# MCU_CTRL_MMR0_MCU_CTRL_MMR_CFG0_04500000h register map
Vendor: Texas Instruments
Registers are 32-bit, read-write, reset 0x0 unless marked. A register's access mark holds for its fields unless they carry their own. Offsets are as the file gives them; [hi:lo] are bit positions; {n}, {i} and the like mark numbered series.

## mcu_ctrl_mmr_CFG0 (part 2 of 2)
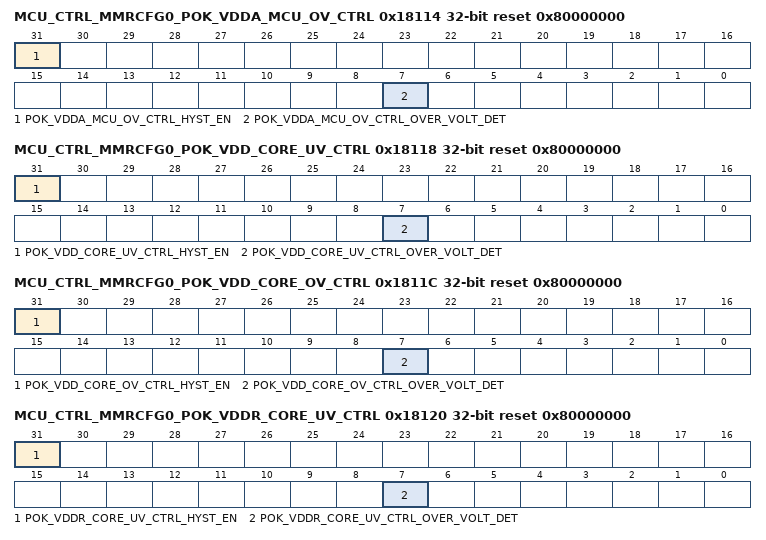
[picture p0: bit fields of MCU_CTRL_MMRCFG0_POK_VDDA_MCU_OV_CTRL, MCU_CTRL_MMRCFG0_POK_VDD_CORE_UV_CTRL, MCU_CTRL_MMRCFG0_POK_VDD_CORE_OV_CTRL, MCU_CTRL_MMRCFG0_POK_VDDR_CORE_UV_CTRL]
0x18114 MCU_CTRL_MMRCFG0_POK_VDDA_MCU_OV_CTRL reset 0x80000000 — Hysterisis, Threshold, and Control of VDDA_MCU 1P8 Under/Over Voltage Monitors in POR (POKHV, POKLVA)
  [31] POK_VDDA_MCU_OV_CTRL_HYST_EN — Enable POK hysteresisField values (others are reserved):1'b0 - DISABLE1'b1 - ENABLE Reset Source: mod_por_rst_n
  [7] POK_VDDA_MCU_OV_CTRL_OVER_VOLT_DET — Over / under voltage detection modeField values (others are reserved):1'b0 - UNDERVOLTAGE_MODE1'b1 - OVERVOLTAGE_MODE Reset Source: mod_por_rst_n
0x18118 MCU_CTRL_MMRCFG0_POK_VDD_CORE_UV_CTRL reset 0x80000000 — Hysterisis, Threshold, and Control of VDD_CORE Under/Over Voltage Monitors in POR (POKLVB) and POK_VDD_CORE_UV
  [31] POK_VDD_CORE_UV_CTRL_HYST_EN — Enable POK hysteresisField values (others are reserved):1'b0 - DISABLE1'b1 - ENABLE Reset Source: mod_por_rst_n
  [7] POK_VDD_CORE_UV_CTRL_OVER_VOLT_DET — Over / under voltage detection modeField values (others are reserved):1'b0 - UNDERVOLTAGE_MODE1'b1 - OVERVOLTAGE_MODE Reset Source: mod_por_rst_n
0x1811C MCU_CTRL_MMRCFG0_POK_VDD_CORE_OV_CTRL reset 0x80000000 — Hysterisis, Threshold, and Control of VDD_CORE Under/Over Voltage Monitors in POR (POKLVB) and POK_VDD_CORE_UV
  [31] POK_VDD_CORE_OV_CTRL_HYST_EN — Enable POK hysteresisField values (others are reserved):1'b0 - DISABLE1'b1 - ENABLE Reset Source: mod_por_rst_n
  [7] POK_VDD_CORE_OV_CTRL_OVER_VOLT_DET — Over / under voltage detection modeField values (others are reserved):1'b0 - UNDERVOLTAGE_MODE1'b1 - OVERVOLTAGE_MODE Reset Source: mod_por_rst_n
0x18120 MCU_CTRL_MMRCFG0_POK_VDDR_CORE_UV_CTRL reset 0x80000000 — Hysterisis, Threshold, and Control of VDDR_CORE Under/Over Voltage Monitor
  [31] POK_VDDR_CORE_UV_CTRL_HYST_EN — Enable POK hysteresisField values (others are reserved):1'b0 - DISABLE1'b1 - ENABLE Reset Source: mod_por_rst_n
  [7] POK_VDDR_CORE_UV_CTRL_OVER_VOLT_DET — Over / under voltage detection modeField values (others are reserved):1'b0 - UNDERVOLTAGE_MODE1'b1 - OVERVOLTAGE_MODE Reset Source: mod_por_rst_n
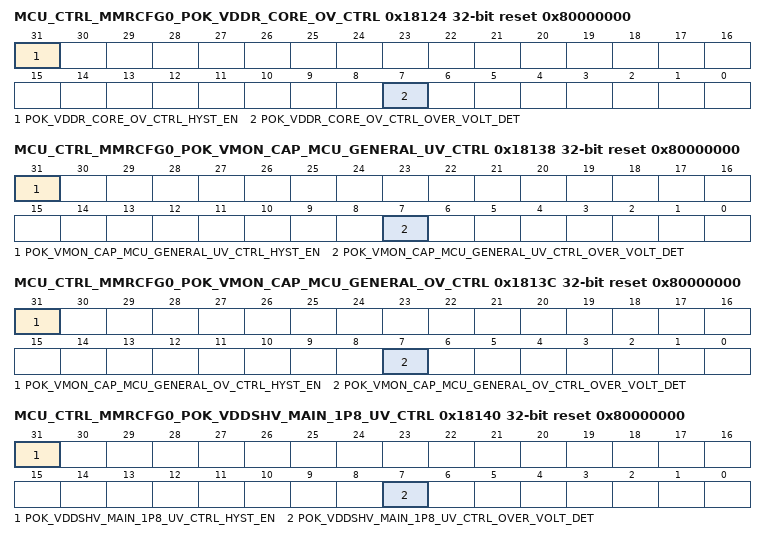
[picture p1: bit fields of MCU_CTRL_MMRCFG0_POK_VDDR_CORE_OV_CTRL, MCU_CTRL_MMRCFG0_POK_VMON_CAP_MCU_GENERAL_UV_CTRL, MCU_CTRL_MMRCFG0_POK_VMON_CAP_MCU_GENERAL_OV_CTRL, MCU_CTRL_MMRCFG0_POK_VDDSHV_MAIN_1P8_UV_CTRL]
0x18124 MCU_CTRL_MMRCFG0_POK_VDDR_CORE_OV_CTRL reset 0x80000000 — Hysterisis, Threshold, and Control of VDDR_CORE Under/Over Voltage Monitor
  [31] POK_VDDR_CORE_OV_CTRL_HYST_EN — Enable POK hysteresisField values (others are reserved):1'b0 - DISABLE1'b1 - ENABLE Reset Source: mod_por_rst_n
  [7] POK_VDDR_CORE_OV_CTRL_OVER_VOLT_DET — Over / under voltage detection modeField values (others are reserved):1'b0 - UNDERVOLTAGE_MODE1'b1 - OVERVOLTAGE_MODE Reset Source: mod_por_rst_n
0x18138 MCU_CTRL_MMRCFG0_POK_VMON_CAP_MCU_GENERAL_UV_CTRL reset 0x80000000 — Hysterisis, Threshold, and Control of VMON_CAP_MCU_GENERAL Under/Over Voltage Monitor
  [31] POK_VMON_CAP_MCU_GENERAL_UV_CTRL_HYST_EN — Enable POK hysteresisField values (others are reserved):1'b0 - DISABLE1'b1 - ENABLE Reset Source: mod_por_rst_n
  [7] POK_VMON_CAP_MCU_GENERAL_UV_CTRL_OVER_VOLT_DET — Over / under voltage detection modeField values (others are reserved):1'b0 - UNDERVOLTAGE_MODE1'b1 - OVERVOLTAGE_MODE Reset Source: mod_por_rst_n
0x1813C MCU_CTRL_MMRCFG0_POK_VMON_CAP_MCU_GENERAL_OV_CTRL reset 0x80000000 — Hysterisis, Threshold, and Control of VMON_CAP_MCU_GENERAL Under/Over Voltage Monitor
  [31] POK_VMON_CAP_MCU_GENERAL_OV_CTRL_HYST_EN — Enable POK hysteresisField values (others are reserved):1'b0 - DISABLE1'b1 - ENABLE Reset Source: mod_por_rst_n
  [7] POK_VMON_CAP_MCU_GENERAL_OV_CTRL_OVER_VOLT_DET — Over / under voltage detection modeField values (others are reserved):1'b0 - UNDERVOLTAGE_MODE1'b1 - OVERVOLTAGE_MODE Reset Source: mod_por_rst_n
0x18140 MCU_CTRL_MMRCFG0_POK_VDDSHV_MAIN_1P8_UV_CTRL reset 0x80000000 — Hysterisis, Threshold, and Control of VDDSHV_MAIN_1P8 Under/Over Voltage Monitor
  [31] POK_VDDSHV_MAIN_1P8_UV_CTRL_HYST_EN — Enable POK hysteresisField values (others are reserved):1'b0 - DISABLE1'b1 - ENABLE Reset Source: mod_por_rst_n
  [7] POK_VDDSHV_MAIN_1P8_UV_CTRL_OVER_VOLT_DET — Over / under voltage detection modeField values (others are reserved):1'b0 - UNDERVOLTAGE_MODE1'b1 - OVERVOLTAGE_MODE Reset Source: mod_por_rst_n
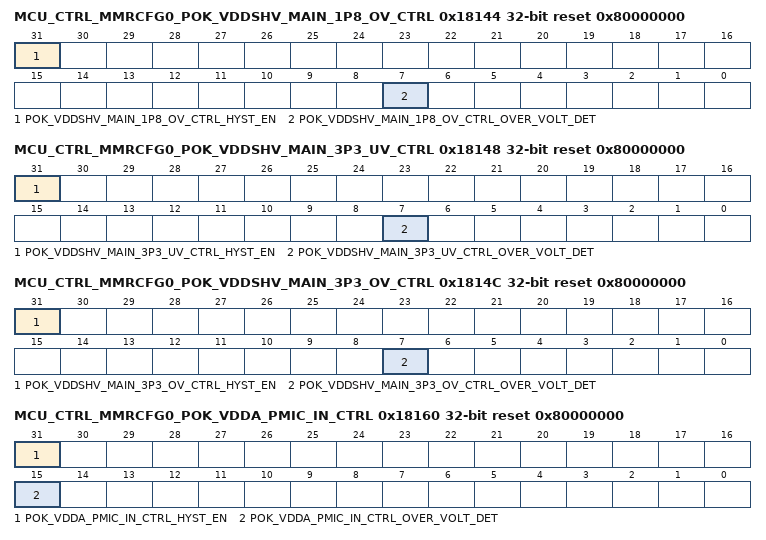
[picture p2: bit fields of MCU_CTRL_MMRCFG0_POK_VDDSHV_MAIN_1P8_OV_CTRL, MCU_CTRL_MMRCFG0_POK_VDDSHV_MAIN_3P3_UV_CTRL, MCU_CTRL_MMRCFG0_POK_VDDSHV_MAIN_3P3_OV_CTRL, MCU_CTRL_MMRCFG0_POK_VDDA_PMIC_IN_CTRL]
0x18144 MCU_CTRL_MMRCFG0_POK_VDDSHV_MAIN_1P8_OV_CTRL reset 0x80000000 — Hysterisis, Threshold, and Control of VDDSHV_MAIN_1P8 Under/Over Voltage Monitor
  [31] POK_VDDSHV_MAIN_1P8_OV_CTRL_HYST_EN — Enable POK hysteresisField values (others are reserved):1'b0 - DISABLE1'b1 - ENABLE Reset Source: mod_por_rst_n
  [7] POK_VDDSHV_MAIN_1P8_OV_CTRL_OVER_VOLT_DET — Over / under voltage detection modeField values (others are reserved):1'b0 - UNDERVOLTAGE_MODE1'b1 - OVERVOLTAGE_MODE Reset Source: mod_por_rst_n
0x18148 MCU_CTRL_MMRCFG0_POK_VDDSHV_MAIN_3P3_UV_CTRL reset 0x80000000 — Hysterisis, Threshold, and Control of VDDSHV_MAIN_3P3 Under/Over Voltage Monitor
  [31] POK_VDDSHV_MAIN_3P3_UV_CTRL_HYST_EN — Enable POK hysteresisField values (others are reserved):1'b0 - DISABLE1'b1 - ENABLE Reset Source: mod_por_rst_n
  [7] POK_VDDSHV_MAIN_3P3_UV_CTRL_OVER_VOLT_DET — Over / under voltage detection modeField values (others are reserved):1'b0 - UNDERVOLTAGE_MODE1'b1 - OVERVOLTAGE_MODE Reset Source: mod_por_rst_n
0x1814C MCU_CTRL_MMRCFG0_POK_VDDSHV_MAIN_3P3_OV_CTRL reset 0x80000000 — Hysterisis, Threshold, and Control of VDDSHV_MAIN_3P3 Under/Over Voltage Monitor
  [31] POK_VDDSHV_MAIN_3P3_OV_CTRL_HYST_EN — Enable POK hysteresisField values (others are reserved):1'b0 - DISABLE1'b1 - ENABLE Reset Source: mod_por_rst_n
  [7] POK_VDDSHV_MAIN_3P3_OV_CTRL_OVER_VOLT_DET — Over / under voltage detection modeField values (others are reserved):1'b0 - UNDERVOLTAGE_MODE1'b1 - OVERVOLTAGE_MODE Reset Source: mod_por_rst_n
0x18160 MCU_CTRL_MMRCFG0_POK_VDDA_PMIC_IN_CTRL reset 0x80000000 — Hysterisis and Control of VDDA_PMIC_IN Under/Over Voltage Monitor
  [31] POK_VDDA_PMIC_IN_CTRL_HYST_EN — Enable POK hysteresisField values (others are reserved):1'b0 - DISABLE1'b1 - ENABLE Reset Source: mod_por_rst_n
  [15] POK_VDDA_PMIC_IN_CTRL_OVER_VOLT_DET — Over / under voltage detection modeField values (others are reserved):1'b0 - UNDERVOLTAGE_MODE1'b1 - OVERVOLTAGE_MODE Reset Source: mod_por_rst_n
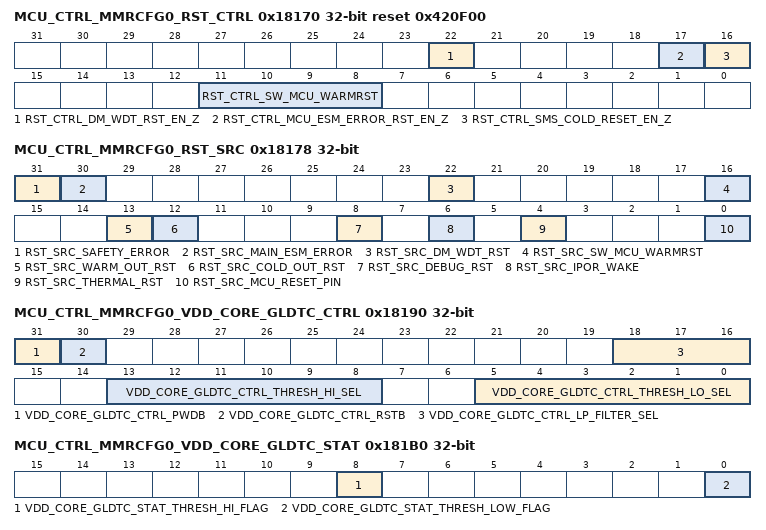
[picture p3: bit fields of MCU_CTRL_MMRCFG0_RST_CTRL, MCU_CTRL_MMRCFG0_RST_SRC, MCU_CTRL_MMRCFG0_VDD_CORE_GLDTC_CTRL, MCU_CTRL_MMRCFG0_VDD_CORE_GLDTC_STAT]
0x18170 MCU_CTRL_MMRCFG0_RST_CTRL reset 0x420F00 — Controls Reset Assertion and Propogation
  [22] RST_CTRL_DM_WDT_RST_EN_Z — Block Reset from DM WDT propogating to MCU domainField values (others are reserved):1'b0 - PROPOGATE1'b1 - BLOCK Reset Source: mcu_chip1_rst_n
  [17] RST_CTRL_MCU_ESM_ERROR_RST_EN_Z — Block Reset of MCU by ESMField values (others are reserved):1'b0 - PROPOGATE1'b1 - BLOCK Reset Source: mcu_chip1_rst_n
  [16] RST_CTRL_SMS_COLD_RESET_EN_Z — Block Reset of MCU by SMSField values (others are reserved):1'b0 - PROPOGATE1'b1 - BLOCK Reset Source: mcu_chip1_rst_n
  [11:8] RST_CTRL_SW_MCU_WARMRST — Causes full device Warm Reset. This is a fault tolerant bitfield. Automatically resets to 4'b1111 after write.Field values (others are reserved):4'b0110 - FORCE_RESET4'b1111 - INACTIVE Reset Source: mcu_chip1_rst_n
0x18174 MCU_CTRL_MMRCFG0_RST_STAT ro — Reset Status
  [0] RST_STAT_MAIN_RESETSTATZ — Status of Main Domain Reset:Field values (others are reserved):1'b0 - BLOCKED1'b1 - PROPOGATE Reset Source: mcu_chip1_rst_n
0x18178 MCU_CTRL_MMRCFG0_RST_SRC access not given — Captures Reason for Warm and Main Domain Power On Resets
  [31] RST_SRC_SAFETY_ERROR — Reset Caused by MCU ESM Error. Write 1 to Clear.Field values (others are reserved):1'b0 - UNKNOWN1'b1 - DETECTED Reset Source: mod_por_rst_n (access R/W1TC)
  [30] RST_SRC_MAIN_ESM_ERROR — Reset Caused by Main ESM Error. Write 1 to Clear.Field values (others are reserved):1'b0 - UNKNOWN1'b1 - DETECTED Reset Source: mod_por_rst_n (access R/W1TC)
  [22] RST_SRC_DM_WDT_RST — Watchdog Initiated Reset. Write 1 to Clear.Field values (others are reserved):1'b0 - UNKNOWN1'b1 - DETECTED Reset Source: mod_por_rst_n (access R/W1TC)
  [16] RST_SRC_SW_MCU_WARMRST — Software Warm Reset. Write 1 to Clear.Field values (others are reserved):1'b0 - UNKNOWN1'b1 - DETECTED Reset Source: mod_por_rst_n (access R/W1TC)
  [13] RST_SRC_WARM_OUT_RST — SMS Warm Reset. Write 1 to Clear.Field values (others are reserved):1'b0 - UNKNOWN1'b1 - DETECTED Reset Source: mod_por_rst_n (access R/W1TC)
  [12] RST_SRC_COLD_OUT_RST — When set, indicates that a DMSC Cold reset occurred and reset either main or mcu domains (or both).Write 1 to clear this bit.Field values (others are reserved):1'b0 - UNKNOWN1'b1 - DETECTED Reset Source: mod_por_rst_n (access R/W1TC)
  [8] RST_SRC_DEBUG_RST — Debug Subsystem Initiated Reset. Write 1 to Clear.Field values (others are reserved):1'b0 - UNKNOWN1'b1 - DETECTED Reset Source: mod_por_rst_n (access R/W1TC)
  [6] RST_SRC_IPOR_WAKE — Wake Event Monitor Internal Power On Reset. Write 1 to ClearField values (others are reserved):1'b0 - UNKNOWN1'b1 - DETECTED Reset Source: por_boot_cfg_rst_n (access R/W1TC)
  [4] RST_SRC_THERMAL_RST — Thermal Reset. Write 1 to Clear.Field values (others are reserved):1'b0 - UNKNOWN1'b1 - DETECTED Reset Source: mod_por_rst_n (access R/W1TC)
  [0] RST_SRC_MCU_RESET_PIN — Reset Caused by MCU Reset Pin. Write 1 to Clear.Field values (others are reserved):1'b0 - UNKNOWN1'b1 - DETECTED Reset Source: mod_por_rst_n (access R/W1TC)
0x18190 MCU_CTRL_MMRCFG0_VDD_CORE_GLDTC_CTRL — Controls the voltage glitch detector circuit monitoring the VDD_CORE voltage domain
  [31] VDD_CORE_GLDTC_CTRL_PWDB — Power down - active low. Field values (others are reserved):1'b0 - PWRDN1'b1 - PWRUP Reset Source: mcu_chip1_rst_n
  [30] VDD_CORE_GLDTC_CTRL_RSTB — Reset - active low. To ensure proper operation, rstb must be not be de-asserted for at least 100 ns after power-up (pwdb de-asserted). Additionally, rstb must be toggled low at least 200 ns after any change in threshold or low-pass filter settings to prevent abnormal trigger events.Field values (others are reserved):1'b0 - RESET1'b1 - ACTIVE Reset Source: mcu_chip1_rst_n
  [18:16] VDD_CORE_GLDTC_CTRL_LP_FILTER_SEL — Selects the glitch detect low-pass filter bandwidthField values (others are reserved):3'b000 - BW_150KHz3'b001 - BW_125KHz3'b010 - BW_100KHz3'b011 - BW_80KHz3'b100 - BW_60KHz3'b101 - BW_45KHz3'b110 - BW_30KHz3'b111 - BW_15KHz Reset Source: mcu_chip1_rst_n
  [13:8] VDD_CORE_GLDTC_CTRL_THRESH_HI_SEL — Selects the high voltage glitch threshold as a percentage of the monitored voltageField values (others are reserved):6'b000000 - PCT_VDD_93P56'b000001 - PCT_VDD_946'b000010 - PCT_VDD_94P56'b000011 - PCT_VDD_956'b000100 - PCT_VDD_95P56'b000101 - PCT_VDD_966'b000110 - PCT_VDD_96P56'b000111 - PCT_VDD_976'b001000 - PCT_VDD_97P56'b001001 - PCT_VDD_986'b001010 - PCT_VDD_98P56'b001011 - PCT_VDD_996'b001100 - PCT_VDD_99P56'b001101 - PCT_VDD_1006'b001110 - PCT_VDD_100P56'b001111 - PCT_VDD_1016'b010000 - PCT_VDD_101P56'b010001 - PCT_VDD_1026'b010010 - PCT_VDD_102P56'b010011 - PCT_VDD_1036'b010100 - PCT_VDD_103P56'b010101 - PCT_VDD_1046'b010110 - PCT_VDD_104P56'b010111 - PCT_VDD_1056'b011000 - PCT_VDD_105P56'b011001 - PCT_VDD_1066'b011010 - PCT_VDD_106P56'b011011 - PCT_VDD_1076'b011100 - PCT_VDD_107P56'b011101 - PCT_VDD_1086'b011110 - PCT_VDD_108P56'b011111 - PCT_VDD_1096'b100000 - PCT_VDD_109P56'b100001 - PCT_VDD_1106'b100010 - PCT_VDD_1116'b100011 - PCT_VDD_1126'b100100 - PCT_VDD_1136'b100101 - PCT_VDD_1146'b100110 - PCT_VDD_1156'b100111 - PCT_VDD_1166'b101000 - PCT_VDD_1176'b101001 - PCT_VDD_1186'b101010 - PCT_VDD_1196'b101011 - PCT_VDD_1206'b101100 - PCT_VDD_1216'b101101 - PCT_VDD_1226'b101110 - PCT_VDD_1236'b101111 - PCT_VDD_1246'b110000 - PCT_VDD_1256'b110001 - PCT_VDD_1266'b110010 - PCT_VDD_1276'b110011 - PCT_VDD_1286'b110100 - PCT_VDD_1296'b110101 - PCT_VDD_1306'b110110 - PCT_VDD_1316'b110111 - PCT_VDD_1326'b111000 - PCT_VDD_1336'b111001 - PCT_VDD_1346'b111010 - PCT_VDD_1356'b111011 - PCT_VDD_1366'b111100 - PCT_VDD_1376'b111101 - PCT_VDD_1386'b111110 - PCT_VDD_1396'b111111 - PCT_VDD_140 Reset Source: mcu_chip1_rst_n
  [5:0] VDD_CORE_GLDTC_CTRL_THRESH_LO_SEL — Selects the low voltage glitch threshold as a percentage of the monitored voltageField values (others are reserved):6'b000000 - PCT_VDD_106P56'b000001 - PCT_VDD_1066'b000010 - PCT_VDD_105P56'b000011 - PCT_VDD_1056'b000100 - PCT_VDD_104P56'b000101 - PCT_VDD_1046'b000110 - PCT_VDD_103P56'b000111 - PCT_VDD_1036'b001000 - PCT_VDD_102P56'b001001 - PCT_VDD_1026'b001010 - PCT_VDD_101P56'b001011 - PCT_VDD_1016'b001100 - PCT_VDD_100P56'b001101 - PCT_VDD_1006'b001110 - PCT_VDD_99P56'b001111 - PCT_VDD_996'b010000 - PCT_VDD_98P56'b010001 - PCT_VDD_986'b010010 - PCT_VDD_97P56'b010011 - PCT_VDD_976'b010100 - PCT_VDD_96P56'b010101 - PCT_VDD_966'b010110 - PCT_VDD_95P56'b010111 - PCT_VDD_956'b011000 - PCT_VDD_94P56'b011001 - PCT_VDD_946'b011010 - PCT_VDD_93P56'b011011 - PCT_VDD_936'b011100 - PCT_VDD_92P56'b011101 - PCT_VDD_926'b011110 - PCT_VDD_91P56'b011111 - PCT_VDD_916'b100000 - PCT_VDD_90P56'b100001 - PCT_VDD_906'b100010 - PCT_VDD_896'b100011 - PCT_VDD_886'b100100 - PCT_VDD_876'b100101 - PCT_VDD_866'b100110 - PCT_VDD_856'b100111 - PCT_VDD_846'b101000 - PCT_VDD_836'b101001 - PCT_VDD_826'b101010 - PCT_VDD_816'b101011 - PCT_VDD_806'b101100 - PCT_VDD_796'b101101 - PCT_VDD_786'b101110 - PCT_VDD_776'b101111 - PCT_VDD_766'b110000 - PCT_VDD_756'b110001 - PCT_VDD_746'b110010 - PCT_VDD_736'b110011 - PCT_VDD_726'b110100 - PCT_VDD_716'b110101 - PCT_VDD_706'b110110 - PCT_VDD_696'b110111 - PCT_VDD_686'b111000 - PCT_VDD_676'b111001 - PCT_VDD_666'b111010 - PCT_VDD_656'b111011 - PCT_VDD_646'b111100 - PCT_VDD_636'b111101 - PCT_VDD_626'b111110 - PCT_VDD_616'b111111 - PCT_VDD_60 Reset Source: mcu_chip1_rst_n
0x181B0 MCU_CTRL_MMRCFG0_VDD_CORE_GLDTC_STAT ro — Shows the status of the voltage glitch detector circuit monitoring the VDD_CORE voltage domain
  [8] VDD_CORE_GLDTC_STAT_THRESH_HI_FLAG — High voltage flag. This flag is cleared by clearing the VDD_CORE_GLDTC_CTRL_rstb bit.Field values (others are reserved):1'b0 - HV_UNKNOWN (not detected)1'b1 - HV_DETECTED Reset Source: mcu_chip1_rst_n
  [0] VDD_CORE_GLDTC_STAT_THRESH_LOW_FLAG — Low voltage flag. This flag is cleared by clearing the VDD_CORE_GLDTC_CTRL_rstb bit.Field values (others are reserved):1'b0 - LV_UNKNOWN (not detected)1'b1 - LV_DETECTED Reset Source: mcu_chip1_rst_n
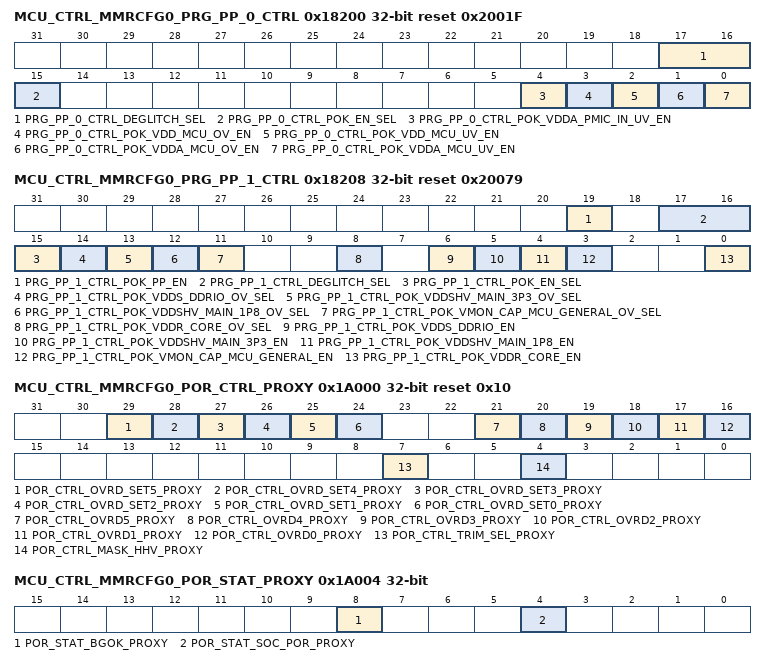
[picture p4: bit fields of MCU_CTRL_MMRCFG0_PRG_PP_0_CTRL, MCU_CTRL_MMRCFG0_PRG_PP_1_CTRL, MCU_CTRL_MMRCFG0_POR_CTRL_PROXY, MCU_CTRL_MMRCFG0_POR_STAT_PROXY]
0x18200 MCU_CTRL_MMRCFG0_PRG_PP_0_CTRL reset 0x2001F — Configures PRG_PP_0 - Fixed POKs (In POR, POKSA, and POK_VDD_CORE_OV)
  [17:16] PRG_PP_0_CTRL_DEGLITCH_SEL — Deglitch period for PRG_PP1 POKs (microseconds)Field values (others are reserved):2'b00 - DG_5_US2'b01 - DG_10_US2'b10 - DG_15_US2'b11 - DG_20_US Reset Source: mod_por_rst_n
  [15] PRG_PP_0_CTRL_POK_EN_SEL — Selects source of POK controlsField values (others are reserved):1'b0 - TIEOFFS1'b1 - PRG_PP0_CTRL_REG Reset Source: mod_por_rst_n
  [4] PRG_PP_0_CTRL_POK_VDDA_PMIC_IN_UV_EN — Enable VDDA_PMIC_IN undervoltage POK detectionField values (others are reserved):1'b0 - Disabled1'b1 - Enabled Reset Source: mod_por_rst_n
  [3] PRG_PP_0_CTRL_POK_VDD_MCU_OV_EN — Enable VDD_MCU overvoltage POK detectionField values (others are reserved):1'b0 - Disabled1'b1 - Enabled Reset Source: mod_por_rst_n
  [2] PRG_PP_0_CTRL_POK_VDD_MCU_UV_EN — Enable VDD_MCU undervoltage POK detectionField values (others are reserved):1'b0 - Disabled1'b1 - Enabled Reset Source: mod_por_rst_n
  [1] PRG_PP_0_CTRL_POK_VDDA_MCU_OV_EN — Enable 1.8V VDDA_MCU overvoltage POK detectionField values (others are reserved):1'b0 - Disabled1'b1 - Enabled Reset Source: mod_por_rst_n
  [0] PRG_PP_0_CTRL_POK_VDDA_MCU_UV_EN — Enable 1.8V VDDA_MCU undervoltage POK detectionField values (others are reserved):1'b0 - Disabled1'b1 - Enabled Reset Source: mod_por_rst_n
0x18208 MCU_CTRL_MMRCFG0_PRG_PP_1_CTRL reset 0x20079 — Configures PRG_PP_1 - Ping-Pong Capable POKs
  [19] PRG_PP_1_CTRL_POK_PP_EN — POK ping-pong enable. When set, POKs with their ov_sel option set to UV_OR_PINGPONG are automatically cycled between UV and OV detection (ping-pong). POKs with ov_sel selecting OV are unaffected by this bit.Field values (others are reserved):1'b0 - UV_FIXED1'b1 - UV_PINGPONG_OV Reset Source: mod_por_rst_n
  [17:16] PRG_PP_1_CTRL_DEGLITCH_SEL — Deglitch period for PRG_PP1 POKs (microseconds)Field values (others are reserved):2'b00 - DG_5_US2'b01 - DG_10_US2'b10 - DG_15_US2'b11 - DG_20_US Reset Source: mod_por_rst_n
  [15] PRG_PP_1_CTRL_POK_EN_SEL — Selects source of POK controlsField values (others are reserved):1'b0 - TIEOFFS1'b1 - PRG_PP0_CTRL_REG Reset Source: mod_por_rst_n
  [14] PRG_PP_1_CTRL_POK_VDDS_DDRIO_OV_SEL — POK_VDDS_DDRIO mode (undervoltage/ping-pong or over-voltage)Field values (others are reserved):1'b0 - UV_OR_PINGPONG1'b1 - OV Reset Source: mod_por_rst_n
  [13] PRG_PP_1_CTRL_POK_VDDSHV_MAIN_3P3_OV_SEL — POK_VDDSHV_MAIN_3P3 mode (undervoltage/ping-pong or over-voltage)Field values (others are reserved):1'b0 - UV_OR_PINGPONG1'b1 - OV Reset Source: mod_por_rst_n
  [12] PRG_PP_1_CTRL_POK_VDDSHV_MAIN_1P8_OV_SEL — POK_VDDSHV_MAIN_1P8 mode (undervoltage/ping-pong or over-voltage)Field values (others are reserved):1'b0 - UV_OR_PINGPONG1'b1 - OV Reset Source: mod_por_rst_n
  [11] PRG_PP_1_CTRL_POK_VMON_CAP_MCU_GENERAL_OV_SEL — POK_VMON_CAP_MCU_GENERAL mode (undervoltage/ping-pong or over-voltage)Field values (others are reserved):1'b0 - UV_OR_PINGPONG1'b1 - OV Reset Source: mod_por_rst_n
  [8] PRG_PP_1_CTRL_POK_VDDR_CORE_OV_SEL — POK_VDDR_CORE mode (undervoltage/ping-pong or over-voltage)Field values (others are reserved):1'b0 - UV_OR_PINGPONG1'b1 - OV Reset Source: mod_por_rst_n
  [6] PRG_PP_1_CTRL_POK_VDDS_DDRIO_EN — Enable POK_VDDS_DDRIO (if pok_en_sel = 1):Field values (others are reserved):1'b0 - Disabled1'b1 - Enabled Reset Source: mod_por_rst_n
  [5] PRG_PP_1_CTRL_POK_VDDSHV_MAIN_3P3_EN — Enable POK_VDDSHV_MAIN_3P3 (if pok_en_sel = 1):Field values (others are reserved):1'b0 - Disabled1'b1 - Enabled Reset Source: mod_por_rst_n
  [4] PRG_PP_1_CTRL_POK_VDDSHV_MAIN_1P8_EN — Enable POK_VDDSHV_MAIN_1P8 (if pok_en_sel = 1):Field values (others are reserved):1'b0 - Disabled1'b1 - Enabled Reset Source: mod_por_rst_n
  [3] PRG_PP_1_CTRL_POK_VMON_CAP_MCU_GENERAL_EN — Enable POK_VMON_CAP_MCU_GENERAL (if pok_en_sel = 1):Field values (others are reserved):1'b0 - Disabled1'b1 - Enabled Reset Source: mod_por_rst_n
  [0] PRG_PP_1_CTRL_POK_VDDR_CORE_EN — Enable POK_VDDR_CORE (if pok_en_sel = 1):Field values (others are reserved):1'b0 - Disabled1'b1 - Enabled Reset Source: mod_por_rst_n
0x18280 MCU_CTRL_MMRCFG0_CLKGATE_CTRL — Controls the power clock gating feature of MCU domain modules and busses
  [0] CLKGATE_CTRL_WKUP_SAFE_CBA_NOGATE — WKUP domain CBASS auto clock gate on idle disable. Field values (others are reserved):1'b0 - Auto clock gating enabled1'b1 - Auto clock gating disabled Reset Source: mod_por_rst_n
0x19008 MCU_CTRL_MMRCFG0_LOCK6_KICK0
  [31:0] LOCK6_KICK0 — - KICK0 component Reset Source: mod_g_rst_n
0x1900C MCU_CTRL_MMRCFG0_LOCK6_KICK1
  [31:0] LOCK6_KICK1 — - KICK1 component Reset Source: mod_g_rst_n
0x19100 MCU_CTRL_MMRCFG0_CLAIMREG_P6_R0_READONLY ro
  [31:0] CLAIMREG_P6_R0_READONLY — Claim bits for Partition 6 Reset Source: mod_g_rst_n
{0x19100+4i} MCU_CTRL_MMRCFG0_CLAIMREG_P6_R{i}_READONLY ro (i=2..5)
  [31:0] CLAIMREG_P6_R{i}_READONLY — Claim bits for Partition 6 Reset Source: mod_g_rst_n
0x1A000 MCU_CTRL_MMRCFG0_POR_CTRL_PROXY reset 0x10 — Configures POR module reset behavior and allows software to directly override POR comparator outputs.
  [29] POR_CTRL_OVRD_SET5_PROXY — Override value when override is active, for RESERVED output.Field values (others are reserved):1'b0 - OVERRIDE_TO_01'b1 - OVERRIDE_TO_1 Reset Source: mod_por_rst_n
  [28] POR_CTRL_OVRD_SET4_PROXY — Override value when override is active, for POKLVB output.Field values (others are reserved):1'b0 - OVERRIDE_TO_01'b1 - OVERRIDE_TO_1 Reset Source: mod_por_rst_n
  [27] POR_CTRL_OVRD_SET3_PROXY — Override value when override is active, for POKLVA output.Field values (others are reserved):1'b0 - OVERRIDE_TO_01'b1 - OVERRIDE_TO_1 Reset Source: mod_por_rst_n
  [26] POR_CTRL_OVRD_SET2_PROXY — Override value when override is active, for POKHV output.Field values (others are reserved):1'b0 - OVERRIDE_TO_01'b1 - OVERRIDE_TO_1 Reset Source: mod_por_rst_n
  [25] POR_CTRL_OVRD_SET1_PROXY — Override value when override is active, for BGOK output.Field values (others are reserved):1'b0 - OVERRIDE_TO_01'b1 - OVERRIDE_TO_1 Reset Source: mod_por_rst_n
  [24] POR_CTRL_OVRD_SET0_PROXY — Override value when override is active, for PORHV output.Field values (others are reserved):1'b0 - OVERRIDE_TO_01'b1 - OVERRIDE_TO_1 Reset Source: mod_por_rst_n
  [21] POR_CTRL_OVRD5_PROXY — Enables override of RESERVED outputField values (others are reserved):1'b0 - NORMAL_OPERATION1'b1 - OVERRIDE_OUTPUT Reset Source: mod_por_rst_n
  [20] POR_CTRL_OVRD4_PROXY — Enables override of POKLVB outputField values (others are reserved):1'b0 - NORMAL_OPERATION1'b1 - OVERRIDE_OUTPUT Reset Source: mod_por_rst_n
  [19] POR_CTRL_OVRD3_PROXY — Enables override of POKLVA outputField values (others are reserved):1'b0 - NORMAL_OPERATION1'b1 - OVERRIDE_OUTPUT Reset Source: mod_por_rst_n
  [18] POR_CTRL_OVRD2_PROXY — Enables override of POKHV outputField values (others are reserved):1'b0 - NORMAL_OPERATION1'b1 - OVERRIDE_OUTPUT Reset Source: mod_por_rst_n
  [17] POR_CTRL_OVRD1_PROXY — Enables override of BGOK outputField values (others are reserved):1'b0 - NORMAL_OPERATION1'b1 - OVERRIDE_OUTPUT Reset Source: mod_por_rst_n
  [16] POR_CTRL_OVRD0_PROXY — Enables override of PORHV outputField values (others are reserved):1'b0 - NORMAL_OPERATION1'b1 - OVERRIDE_OUTPUT Reset Source: mod_por_rst_n
  [7] POR_CTRL_TRIM_SEL_PROXY — POR Trim Select - Fixed value or from POR_BANDGAP_CTRL and POR_POKxxx_CTRL registers MMRsField values (others are reserved):1'b0 - FIXED_TRIM1'b1 - MMR_TRIM Reset Source: mod_por_rst_n
  [4] POR_CTRL_MASK_HHV_PROXY — Mask HHV/SOC_PORz outputs when applying new trim valuesField values (others are reserved):1'b0 - UNMASK1'b1 - MASK Reset Source: mod_por_rst_n
0x1A004 MCU_CTRL_MMRCFG0_POR_STAT_PROXY ro — Shows POR module status
  [8] POR_STAT_BGOK_PROXY — Bandgap OK statusField values (others are reserved):1'b0 - UNKNOWN1'b1 - OK Reset Source: mod_por_rst_n
  [4] POR_STAT_SOC_POR_PROXY — POR module statusField values (others are reserved):1'b0 - POR_IS_ACTIVE1'b1 - POR_IS_RESET Reset Source: mod_por_rst_n
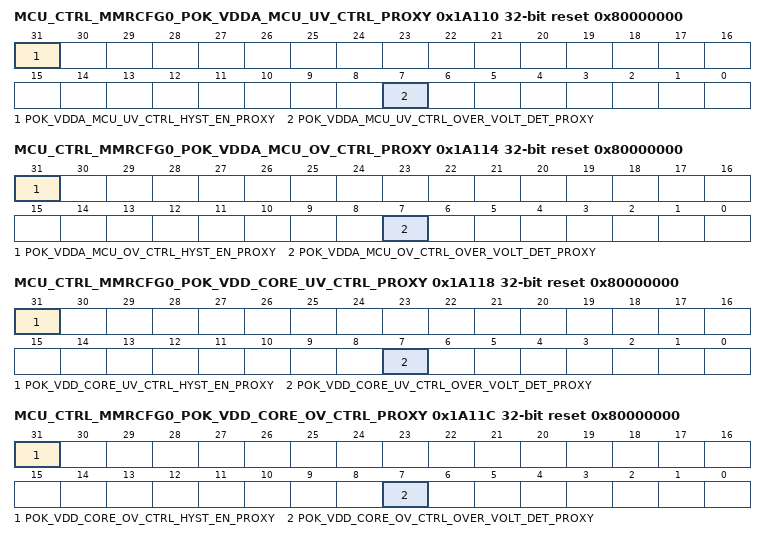
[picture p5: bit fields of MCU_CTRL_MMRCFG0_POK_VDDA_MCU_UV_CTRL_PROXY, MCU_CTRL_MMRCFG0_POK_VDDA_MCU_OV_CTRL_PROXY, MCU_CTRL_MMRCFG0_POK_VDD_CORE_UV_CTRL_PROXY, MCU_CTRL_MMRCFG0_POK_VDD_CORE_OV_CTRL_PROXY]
0x1A110 MCU_CTRL_MMRCFG0_POK_VDDA_MCU_UV_CTRL_PROXY reset 0x80000000 — Hysterisis, Threshold, and Control of VDDA_MCU 1P8 Under/Over Voltage Monitors in POR (POKHV, POKLVA)
  [31] POK_VDDA_MCU_UV_CTRL_HYST_EN_PROXY — Enable POK hysteresisField values (others are reserved):1'b0 - DISABLE1'b1 - ENABLE Reset Source: mod_por_rst_n
  [7] POK_VDDA_MCU_UV_CTRL_OVER_VOLT_DET_PROXY — Over / under voltage detection modeField values (others are reserved):1'b0 - UNDERVOLTAGE_MODE1'b1 - OVERVOLTAGE_MODE Reset Source: mod_por_rst_n
0x1A114 MCU_CTRL_MMRCFG0_POK_VDDA_MCU_OV_CTRL_PROXY reset 0x80000000 — Hysterisis, Threshold, and Control of VDDA_MCU 1P8 Under/Over Voltage Monitors in POR (POKHV, POKLVA)
  [31] POK_VDDA_MCU_OV_CTRL_HYST_EN_PROXY — Enable POK hysteresisField values (others are reserved):1'b0 - DISABLE1'b1 - ENABLE Reset Source: mod_por_rst_n
  [7] POK_VDDA_MCU_OV_CTRL_OVER_VOLT_DET_PROXY — Over / under voltage detection modeField values (others are reserved):1'b0 - UNDERVOLTAGE_MODE1'b1 - OVERVOLTAGE_MODE Reset Source: mod_por_rst_n
0x1A118 MCU_CTRL_MMRCFG0_POK_VDD_CORE_UV_CTRL_PROXY reset 0x80000000 — Hysterisis, Threshold, and Control of VDD_CORE Under/Over Voltage Monitors in POR (POKLVB) and POK_VDD_CORE_UV
  [31] POK_VDD_CORE_UV_CTRL_HYST_EN_PROXY — Enable POK hysteresisField values (others are reserved):1'b0 - DISABLE1'b1 - ENABLE Reset Source: mod_por_rst_n
  [7] POK_VDD_CORE_UV_CTRL_OVER_VOLT_DET_PROXY — Over / under voltage detection modeField values (others are reserved):1'b0 - UNDERVOLTAGE_MODE1'b1 - OVERVOLTAGE_MODE Reset Source: mod_por_rst_n
0x1A11C MCU_CTRL_MMRCFG0_POK_VDD_CORE_OV_CTRL_PROXY reset 0x80000000 — Hysterisis, Threshold, and Control of VDD_CORE Under/Over Voltage Monitors in POR (POKLVB) and POK_VDD_CORE_UV
  [31] POK_VDD_CORE_OV_CTRL_HYST_EN_PROXY — Enable POK hysteresisField values (others are reserved):1'b0 - DISABLE1'b1 - ENABLE Reset Source: mod_por_rst_n
  [7] POK_VDD_CORE_OV_CTRL_OVER_VOLT_DET_PROXY — Over / under voltage detection modeField values (others are reserved):1'b0 - UNDERVOLTAGE_MODE1'b1 - OVERVOLTAGE_MODE Reset Source: mod_por_rst_n
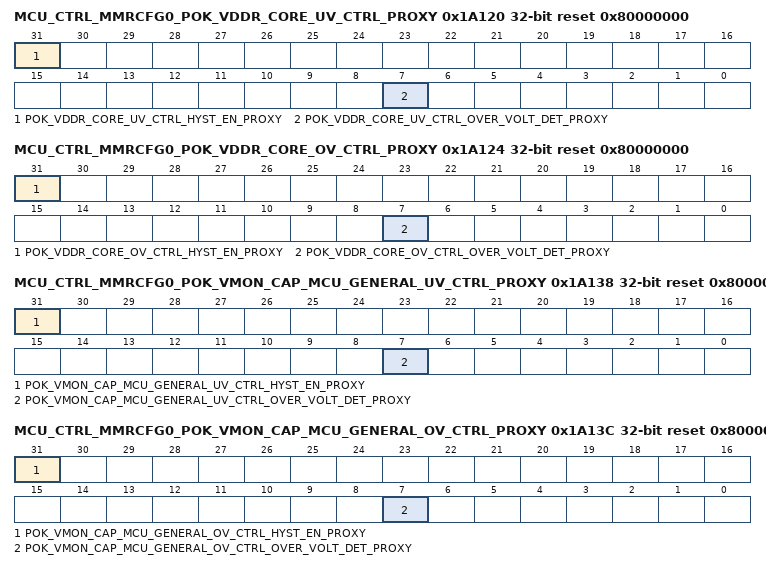
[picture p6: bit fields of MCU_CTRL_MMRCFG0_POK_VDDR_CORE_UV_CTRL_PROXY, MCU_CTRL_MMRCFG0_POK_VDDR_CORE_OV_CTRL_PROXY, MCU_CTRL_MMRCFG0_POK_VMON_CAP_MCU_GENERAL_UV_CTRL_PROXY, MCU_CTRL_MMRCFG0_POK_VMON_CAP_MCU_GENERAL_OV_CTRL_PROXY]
0x1A120 MCU_CTRL_MMRCFG0_POK_VDDR_CORE_UV_CTRL_PROXY reset 0x80000000 — Hysterisis, Threshold, and Control of VDDR_CORE Under/Over Voltage Monitor
  [31] POK_VDDR_CORE_UV_CTRL_HYST_EN_PROXY — Enable POK hysteresisField values (others are reserved):1'b0 - DISABLE1'b1 - ENABLE Reset Source: mod_por_rst_n
  [7] POK_VDDR_CORE_UV_CTRL_OVER_VOLT_DET_PROXY — Over / under voltage detection modeField values (others are reserved):1'b0 - UNDERVOLTAGE_MODE1'b1 - OVERVOLTAGE_MODE Reset Source: mod_por_rst_n
0x1A124 MCU_CTRL_MMRCFG0_POK_VDDR_CORE_OV_CTRL_PROXY reset 0x80000000 — Hysterisis, Threshold, and Control of VDDR_CORE Under/Over Voltage Monitor
  [31] POK_VDDR_CORE_OV_CTRL_HYST_EN_PROXY — Enable POK hysteresisField values (others are reserved):1'b0 - DISABLE1'b1 - ENABLE Reset Source: mod_por_rst_n
  [7] POK_VDDR_CORE_OV_CTRL_OVER_VOLT_DET_PROXY — Over / under voltage detection modeField values (others are reserved):1'b0 - UNDERVOLTAGE_MODE1'b1 - OVERVOLTAGE_MODE Reset Source: mod_por_rst_n
0x1A138 MCU_CTRL_MMRCFG0_POK_VMON_CAP_MCU_GENERAL_UV_CTRL_PROXY reset 0x80000000 — Hysterisis, Threshold, and Control of VMON_CAP_MCU_GENERAL Under/Over Voltage Monitor
  [31] POK_VMON_CAP_MCU_GENERAL_UV_CTRL_HYST_EN_PROXY — Enable POK hysteresisField values (others are reserved):1'b0 - DISABLE1'b1 - ENABLE Reset Source: mod_por_rst_n
  [7] POK_VMON_CAP_MCU_GENERAL_UV_CTRL_OVER_VOLT_DET_PROXY — Over / under voltage detection modeField values (others are reserved):1'b0 - UNDERVOLTAGE_MODE1'b1 - OVERVOLTAGE_MODE Reset Source: mod_por_rst_n
0x1A13C MCU_CTRL_MMRCFG0_POK_VMON_CAP_MCU_GENERAL_OV_CTRL_PROXY reset 0x80000000 — Hysterisis, Threshold, and Control of VMON_CAP_MCU_GENERAL Under/Over Voltage Monitor
  [31] POK_VMON_CAP_MCU_GENERAL_OV_CTRL_HYST_EN_PROXY — Enable POK hysteresisField values (others are reserved):1'b0 - DISABLE1'b1 - ENABLE Reset Source: mod_por_rst_n
  [7] POK_VMON_CAP_MCU_GENERAL_OV_CTRL_OVER_VOLT_DET_PROXY — Over / under voltage detection modeField values (others are reserved):1'b0 - UNDERVOLTAGE_MODE1'b1 - OVERVOLTAGE_MODE Reset Source: mod_por_rst_n
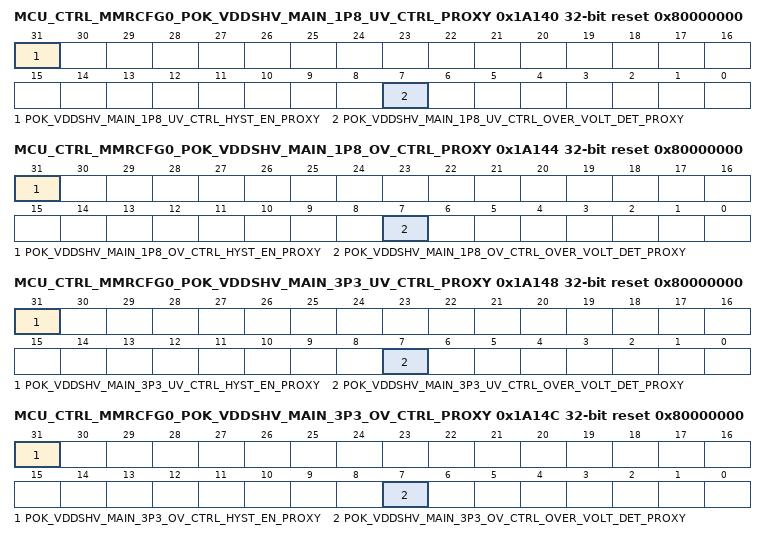
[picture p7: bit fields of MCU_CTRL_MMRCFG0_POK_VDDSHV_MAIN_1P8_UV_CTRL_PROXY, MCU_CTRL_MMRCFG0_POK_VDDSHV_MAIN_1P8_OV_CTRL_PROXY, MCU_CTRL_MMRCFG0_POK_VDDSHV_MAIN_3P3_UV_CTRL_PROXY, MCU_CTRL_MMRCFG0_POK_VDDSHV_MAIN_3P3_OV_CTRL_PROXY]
0x1A140 MCU_CTRL_MMRCFG0_POK_VDDSHV_MAIN_1P8_UV_CTRL_PROXY reset 0x80000000 — Hysterisis, Threshold, and Control of VDDSHV_MAIN_1P8 Under/Over Voltage Monitor
  [31] POK_VDDSHV_MAIN_1P8_UV_CTRL_HYST_EN_PROXY — Enable POK hysteresisField values (others are reserved):1'b0 - DISABLE1'b1 - ENABLE Reset Source: mod_por_rst_n
  [7] POK_VDDSHV_MAIN_1P8_UV_CTRL_OVER_VOLT_DET_PROXY — Over / under voltage detection modeField values (others are reserved):1'b0 - UNDERVOLTAGE_MODE1'b1 - OVERVOLTAGE_MODE Reset Source: mod_por_rst_n
0x1A144 MCU_CTRL_MMRCFG0_POK_VDDSHV_MAIN_1P8_OV_CTRL_PROXY reset 0x80000000 — Hysterisis, Threshold, and Control of VDDSHV_MAIN_1P8 Under/Over Voltage Monitor
  [31] POK_VDDSHV_MAIN_1P8_OV_CTRL_HYST_EN_PROXY — Enable POK hysteresisField values (others are reserved):1'b0 - DISABLE1'b1 - ENABLE Reset Source: mod_por_rst_n
  [7] POK_VDDSHV_MAIN_1P8_OV_CTRL_OVER_VOLT_DET_PROXY — Over / under voltage detection modeField values (others are reserved):1'b0 - UNDERVOLTAGE_MODE1'b1 - OVERVOLTAGE_MODE Reset Source: mod_por_rst_n
0x1A148 MCU_CTRL_MMRCFG0_POK_VDDSHV_MAIN_3P3_UV_CTRL_PROXY reset 0x80000000 — Hysterisis, Threshold, and Control of VDDSHV_MAIN_3P3 Under/Over Voltage Monitor
  [31] POK_VDDSHV_MAIN_3P3_UV_CTRL_HYST_EN_PROXY — Enable POK hysteresisField values (others are reserved):1'b0 - DISABLE1'b1 - ENABLE Reset Source: mod_por_rst_n
  [7] POK_VDDSHV_MAIN_3P3_UV_CTRL_OVER_VOLT_DET_PROXY — Over / under voltage detection modeField values (others are reserved):1'b0 - UNDERVOLTAGE_MODE1'b1 - OVERVOLTAGE_MODE Reset Source: mod_por_rst_n
0x1A14C MCU_CTRL_MMRCFG0_POK_VDDSHV_MAIN_3P3_OV_CTRL_PROXY reset 0x80000000 — Hysterisis, Threshold, and Control of VDDSHV_MAIN_3P3 Under/Over Voltage Monitor
  [31] POK_VDDSHV_MAIN_3P3_OV_CTRL_HYST_EN_PROXY — Enable POK hysteresisField values (others are reserved):1'b0 - DISABLE1'b1 - ENABLE Reset Source: mod_por_rst_n
  [7] POK_VDDSHV_MAIN_3P3_OV_CTRL_OVER_VOLT_DET_PROXY — Over / under voltage detection modeField values (others are reserved):1'b0 - UNDERVOLTAGE_MODE1'b1 - OVERVOLTAGE_MODE Reset Source: mod_por_rst_n
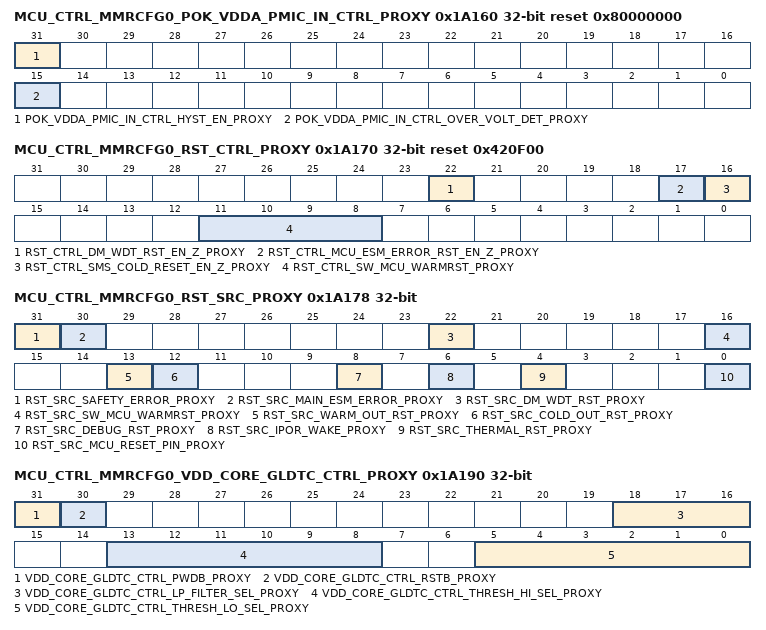
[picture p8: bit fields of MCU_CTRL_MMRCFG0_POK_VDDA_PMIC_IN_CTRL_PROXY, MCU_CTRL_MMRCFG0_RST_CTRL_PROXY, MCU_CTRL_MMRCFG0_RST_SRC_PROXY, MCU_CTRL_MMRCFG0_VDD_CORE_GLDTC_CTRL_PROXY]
0x1A160 MCU_CTRL_MMRCFG0_POK_VDDA_PMIC_IN_CTRL_PROXY reset 0x80000000 — Hysterisis and Control of VDDA_PMIC_IN Under/Over Voltage Monitor
  [31] POK_VDDA_PMIC_IN_CTRL_HYST_EN_PROXY — Enable POK hysteresisField values (others are reserved):1'b0 - DISABLE1'b1 - ENABLE Reset Source: mod_por_rst_n
  [15] POK_VDDA_PMIC_IN_CTRL_OVER_VOLT_DET_PROXY — Over / under voltage detection modeField values (others are reserved):1'b0 - UNDERVOLTAGE_MODE1'b1 - OVERVOLTAGE_MODE Reset Source: mod_por_rst_n
0x1A170 MCU_CTRL_MMRCFG0_RST_CTRL_PROXY reset 0x420F00 — Controls Reset Assertion and Propogation
  [22] RST_CTRL_DM_WDT_RST_EN_Z_PROXY — Block Reset from DM WDT propogating to MCU domainField values (others are reserved):1'b0 - PROPOGATE1'b1 - BLOCK Reset Source: mcu_chip1_rst_n
  [17] RST_CTRL_MCU_ESM_ERROR_RST_EN_Z_PROXY — Block Reset of MCU by ESMField values (others are reserved):1'b0 - PROPOGATE1'b1 - BLOCK Reset Source: mcu_chip1_rst_n
  [16] RST_CTRL_SMS_COLD_RESET_EN_Z_PROXY — Block Reset of MCU by SMSField values (others are reserved):1'b0 - PROPOGATE1'b1 - BLOCK Reset Source: mcu_chip1_rst_n
  [11:8] RST_CTRL_SW_MCU_WARMRST_PROXY — Causes MAIN Domain Warm Reset. This is a fault tolerant bitfield. Automatically resets to 4'b1111 after write.Field values (others are reserved):4'b0110 - FORCE_RESET4'b1111 - INACTIVE Reset Source: mcu_chip1_rst_n
0x1A174 MCU_CTRL_MMRCFG0_RST_STAT_PROXY ro — Reset Status
  [0] RST_STAT_MAIN_RESETSTATZ_PROXY — Status of Main Domain Reset:Field values (others are reserved):1'b0 - BLOCKED1'b1 - PROPOGATE Reset Source: mcu_chip1_rst_n
0x1A178 MCU_CTRL_MMRCFG0_RST_SRC_PROXY access not given — Captures Reason for Warm and Main Domain Power On Resets
  [31] RST_SRC_SAFETY_ERROR_PROXY — Reset Caused by MCU ESM Error. Write 1 to Clear.Field values (others are reserved):1'b0 - UNKNOWN1'b1 - DETECTED Reset Source: mod_por_rst_n (access R/W1TC)
  [30] RST_SRC_MAIN_ESM_ERROR_PROXY — Reset Caused by Main ESM Error. Write 1 to Clear.Field values (others are reserved):1'b0 - UNKNOWN1'b1 - DETECTED Reset Source: mod_por_rst_n (access R/W1TC)
  [22] RST_SRC_DM_WDT_RST_PROXY — Watchdog Initiated Reset. Write 1 to Clear.Field values (others are reserved):1'b0 - UNKNOWN1'b1 - DETECTED Reset Source: mod_por_rst_n (access R/W1TC)
  [16] RST_SRC_SW_MCU_WARMRST_PROXY — Software Warm Reset. Write 1 to Clear.Field values (others are reserved):1'b0 - UNKNOWN1'b1 - DETECTED Reset Source: mod_por_rst_n (access R/W1TC)
  [13] RST_SRC_WARM_OUT_RST_PROXY — SMS Warm Reset. Write 1 to Clear.Field values (others are reserved):1'b0 - UNKNOWN1'b1 - DETECTED Reset Source: mod_por_rst_n (access R/W1TC)
  [12] RST_SRC_COLD_OUT_RST_PROXY — When set, indicates that a DMSC Cold reset occurred and reset either main or mcu domains (or both).Write 1 to clear this bit.Field values (others are reserved):1'b0 - UNKNOWN1'b1 - DETECTED Reset Source: mod_por_rst_n (access R/W1TC)
  [8] RST_SRC_DEBUG_RST_PROXY — Debug Subsystem Initiated Reset. Write 1 to Clear.Field values (others are reserved):1'b0 - UNKNOWN1'b1 - DETECTED Reset Source: mod_por_rst_n (access R/W1TC)
  [6] RST_SRC_IPOR_WAKE_PROXY — Wake Event Monitor Internal Power On Reset. Write 1 to ClearField values (others are reserved):1'b0 - UNKNOWN1'b1 - DETECTED Reset Source: por_boot_cfg_rst_n (access R/W1TC)
  [4] RST_SRC_THERMAL_RST_PROXY — Thermal Reset. Write 1 to Clear.Field values (others are reserved):1'b0 - UNKNOWN1'b1 - DETECTED Reset Source: mod_por_rst_n (access R/W1TC)
  [0] RST_SRC_MCU_RESET_PIN_PROXY — Reset Caused by MCU Reset Pin. Write 1 to Clear.Field values (others are reserved):1'b0 - UNKNOWN1'b1 - DETECTED Reset Source: mod_por_rst_n (access R/W1TC)
0x1A190 MCU_CTRL_MMRCFG0_VDD_CORE_GLDTC_CTRL_PROXY — Controls the voltage glitch detector circuit monitoring the VDD_CORE voltage domain
  [31] VDD_CORE_GLDTC_CTRL_PWDB_PROXY — Power down - active low. Field values (others are reserved):1'b0 - PWRDN1'b1 - PWRUP Reset Source: mcu_chip1_rst_n
  [30] VDD_CORE_GLDTC_CTRL_RSTB_PROXY — Reset - active low. To ensure proper operation, rstb must be not be de-asserted for at least 100 ns after power-up (pwdb de-asserted). Additionally, rstb must be toggled low at least 200 ns after any change in threshold or low-pass filter settings to prevent abnormal trigger events.Field values (others are reserved):1'b0 - RESET1'b1 - ACTIVE Reset Source: mcu_chip1_rst_n
  [18:16] VDD_CORE_GLDTC_CTRL_LP_FILTER_SEL_PROXY — Selects the glitch detect low-pass filter bandwidthField values (others are reserved):3'b000 - BW_150KHz3'b001 - BW_125KHz3'b010 - BW_100KHz3'b011 - BW_80KHz3'b100 - BW_60KHz3'b101 - BW_45KHz3'b110 - BW_30KHz3'b111 - BW_15KHz Reset Source: mcu_chip1_rst_n
  [13:8] VDD_CORE_GLDTC_CTRL_THRESH_HI_SEL_PROXY — Selects the high voltage glitch threshold as a percentage of the monitored voltageField values (others are reserved):6'b000000 - PCT_VDD_93P56'b000001 - PCT_VDD_946'b000010 - PCT_VDD_94P56'b000011 - PCT_VDD_956'b000100 - PCT_VDD_95P56'b000101 - PCT_VDD_966'b000110 - PCT_VDD_96P56'b000111 - PCT_VDD_976'b001000 - PCT_VDD_97P56'b001001 - PCT_VDD_986'b001010 - PCT_VDD_98P56'b001011 - PCT_VDD_996'b001100 - PCT_VDD_99P56'b001101 - PCT_VDD_1006'b001110 - PCT_VDD_100P56'b001111 - PCT_VDD_1016'b010000 - PCT_VDD_101P56'b010001 - PCT_VDD_1026'b010010 - PCT_VDD_102P56'b010011 - PCT_VDD_1036'b010100 - PCT_VDD_103P56'b010101 - PCT_VDD_1046'b010110 - PCT_VDD_104P56'b010111 - PCT_VDD_1056'b011000 - PCT_VDD_105P56'b011001 - PCT_VDD_1066'b011010 - PCT_VDD_106P56'b011011 - PCT_VDD_1076'b011100 - PCT_VDD_107P56'b011101 - PCT_VDD_1086'b011110 - PCT_VDD_108P56'b011111 - PCT_VDD_1096'b100000 - PCT_VDD_109P56'b100001 - PCT_VDD_1106'b100010 - PCT_VDD_1116'b100011 - PCT_VDD_1126'b100100 - PCT_VDD_1136'b100101 - PCT_VDD_1146'b100110 - PCT_VDD_1156'b100111 - PCT_VDD_1166'b101000 - PCT_VDD_1176'b101001 - PCT_VDD_1186'b101010 - PCT_VDD_1196'b101011 - PCT_VDD_1206'b101100 - PCT_VDD_1216'b101101 - PCT_VDD_1226'b101110 - PCT_VDD_1236'b101111 - PCT_VDD_1246'b110000 - PCT_VDD_1256'b110001 - PCT_VDD_1266'b110010 - PCT_VDD_1276'b110011 - PCT_VDD_1286'b110100 - PCT_VDD_1296'b110101 - PCT_VDD_1306'b110110 - PCT_VDD_1316'b110111 - PCT_VDD_1326'b111000 - PCT_VDD_1336'b111001 - PCT_VDD_1346'b111010 - PCT_VDD_1356'b111011 - PCT_VDD_1366'b111100 - PCT_VDD_1376'b111101 - PCT_VDD_1386'b111110 - PCT_VDD_1396'b111111 - PCT_VDD_140 Reset Source: mcu_chip1_rst_n
  [5:0] VDD_CORE_GLDTC_CTRL_THRESH_LO_SEL_PROXY — Selects the low voltage glitch threshold as a percentage of the monitored voltageField values (others are reserved):6'b000000 - PCT_VDD_106P56'b000001 - PCT_VDD_1066'b000010 - PCT_VDD_105P56'b000011 - PCT_VDD_1056'b000100 - PCT_VDD_104P56'b000101 - PCT_VDD_1046'b000110 - PCT_VDD_103P56'b000111 - PCT_VDD_1036'b001000 - PCT_VDD_102P56'b001001 - PCT_VDD_1026'b001010 - PCT_VDD_101P56'b001011 - PCT_VDD_1016'b001100 - PCT_VDD_100P56'b001101 - PCT_VDD_1006'b001110 - PCT_VDD_99P56'b001111 - PCT_VDD_996'b010000 - PCT_VDD_98P56'b010001 - PCT_VDD_986'b010010 - PCT_VDD_97P56'b010011 - PCT_VDD_976'b010100 - PCT_VDD_96P56'b010101 - PCT_VDD_966'b010110 - PCT_VDD_95P56'b010111 - PCT_VDD_956'b011000 - PCT_VDD_94P56'b011001 - PCT_VDD_946'b011010 - PCT_VDD_93P56'b011011 - PCT_VDD_936'b011100 - PCT_VDD_92P56'b011101 - PCT_VDD_926'b011110 - PCT_VDD_91P56'b011111 - PCT_VDD_916'b100000 - PCT_VDD_90P56'b100001 - PCT_VDD_906'b100010 - PCT_VDD_896'b100011 - PCT_VDD_886'b100100 - PCT_VDD_876'b100101 - PCT_VDD_866'b100110 - PCT_VDD_856'b100111 - PCT_VDD_846'b101000 - PCT_VDD_836'b101001 - PCT_VDD_826'b101010 - PCT_VDD_816'b101011 - PCT_VDD_806'b101100 - PCT_VDD_796'b101101 - PCT_VDD_786'b101110 - PCT_VDD_776'b101111 - PCT_VDD_766'b110000 - PCT_VDD_756'b110001 - PCT_VDD_746'b110010 - PCT_VDD_736'b110011 - PCT_VDD_726'b110100 - PCT_VDD_716'b110101 - PCT_VDD_706'b110110 - PCT_VDD_696'b110111 - PCT_VDD_686'b111000 - PCT_VDD_676'b111001 - PCT_VDD_666'b111010 - PCT_VDD_656'b111011 - PCT_VDD_646'b111100 - PCT_VDD_636'b111101 - PCT_VDD_626'b111110 - PCT_VDD_616'b111111 - PCT_VDD_60 Reset Source: mcu_chip1_rst_n
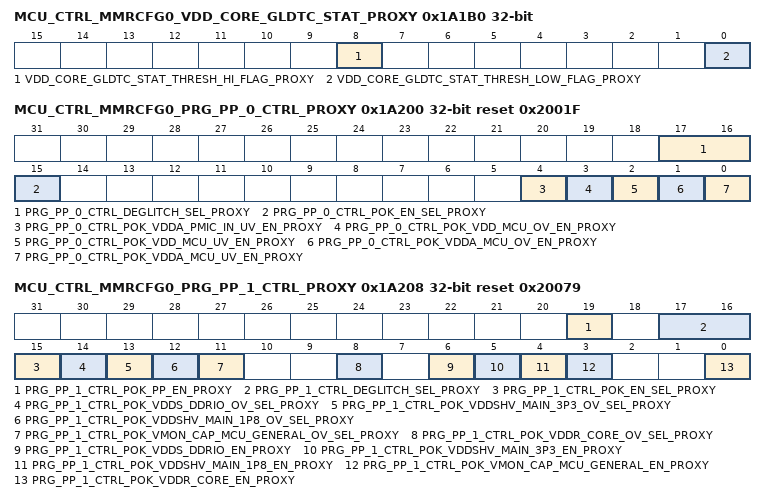
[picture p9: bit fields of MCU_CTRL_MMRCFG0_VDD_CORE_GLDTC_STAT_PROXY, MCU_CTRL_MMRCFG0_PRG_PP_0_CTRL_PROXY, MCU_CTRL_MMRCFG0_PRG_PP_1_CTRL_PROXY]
0x1A1B0 MCU_CTRL_MMRCFG0_VDD_CORE_GLDTC_STAT_PROXY ro — Shows the status of the voltage glitch detector circuit monitoring the VDD_CORE voltage domain
  [8] VDD_CORE_GLDTC_STAT_THRESH_HI_FLAG_PROXY — High voltage flag. This flag is cleared by clearing the VDD_CORE_GLDTC_CTRL_rstb bit.Field values (others are reserved):1'b0 - HV_UNKNOWN (not detected)1'b1 - HV_DETECTED Reset Source: mcu_chip1_rst_n
  [0] VDD_CORE_GLDTC_STAT_THRESH_LOW_FLAG_PROXY — Low voltage flag. This flag is cleared by clearing the VDD_CORE_GLDTC_CTRL_rstb bit.Field values (others are reserved):1'b0 - LV_UNKNOWN (not detected)1'b1 - LV_DETECTED Reset Source: mcu_chip1_rst_n
0x1A200 MCU_CTRL_MMRCFG0_PRG_PP_0_CTRL_PROXY reset 0x2001F — Configures PRG_PP_0 - Fixed POKs (In POR, POKSA, and POK_VDD_CORE_OV)
  [17:16] PRG_PP_0_CTRL_DEGLITCH_SEL_PROXY — Deglitch period for PRG_PP1 POKs (microseconds)Field values (others are reserved):2'b00 - DG_5_US2'b01 - DG_10_US2'b10 - DG_15_US2'b11 - DG_20_US Reset Source: mod_por_rst_n
  [15] PRG_PP_0_CTRL_POK_EN_SEL_PROXY — Selects source of POK controlsField values (others are reserved):1'b0 - TIEOFFS1'b1 - PRG_PP0_CTRL_REG Reset Source: mod_por_rst_n
  [4] PRG_PP_0_CTRL_POK_VDDA_PMIC_IN_UV_EN_PROXY — Enable VDDA_PMIC_IN undervoltage POK detectionField values (others are reserved):1'b0 - Disabled1'b1 - Enabled Reset Source: mod_por_rst_n
  [3] PRG_PP_0_CTRL_POK_VDD_MCU_OV_EN_PROXY — Enable VDD_MCU overvoltage POK detectionField values (others are reserved):1'b0 - Disabled1'b1 - Enabled Reset Source: mod_por_rst_n
  [2] PRG_PP_0_CTRL_POK_VDD_MCU_UV_EN_PROXY — Enable VDD_MCU undervoltage POK detectionField values (others are reserved):1'b0 - Disabled1'b1 - Enabled Reset Source: mod_por_rst_n
  [1] PRG_PP_0_CTRL_POK_VDDA_MCU_OV_EN_PROXY — Enable 1.8V VDDA_MCU overvoltage POK detectionField values (others are reserved):1'b0 - Disabled1'b1 - Enabled Reset Source: mod_por_rst_n
  [0] PRG_PP_0_CTRL_POK_VDDA_MCU_UV_EN_PROXY — Enable 1.8V VDDA_MCU undervoltage POK detectionField values (others are reserved):1'b0 - Disabled1'b1 - Enabled Reset Source: mod_por_rst_n
0x1A208 MCU_CTRL_MMRCFG0_PRG_PP_1_CTRL_PROXY reset 0x20079 — Configures PRG_PP_1 - Ping-Pong Capable POKs
  [19] PRG_PP_1_CTRL_POK_PP_EN_PROXY — POK ping-pong enable. When set, POKs with their ov_sel option set to UV_OR_PINGPONG are automatically cycled between UV and OV detection (ping-pong). POKs with ov_sel selecting OV are unaffected by this bit.Field values (others are reserved):1'b0 - UV_FIXED1'b1 - UV_PINGPONG_OV Reset Source: mod_por_rst_n
  [17:16] PRG_PP_1_CTRL_DEGLITCH_SEL_PROXY — Deglitch period for PRG_PP1 POKs (microseconds)Field values (others are reserved):2'b00 - DG_5_US2'b01 - DG_10_US2'b10 - DG_15_US2'b11 - DG_20_US Reset Source: mod_por_rst_n
  [15] PRG_PP_1_CTRL_POK_EN_SEL_PROXY — Selects source of POK controlsField values (others are reserved):1'b0 - TIEOFFS1'b1 - PRG_PP0_CTRL_REG Reset Source: mod_por_rst_n
  [14] PRG_PP_1_CTRL_POK_VDDS_DDRIO_OV_SEL_PROXY — POK_VDDS_DDRIO mode (undervoltage/ping-pong or over-voltage)Field values (others are reserved):1'b0 - UV_OR_PINGPONG1'b1 - OV Reset Source: mod_por_rst_n
  [13] PRG_PP_1_CTRL_POK_VDDSHV_MAIN_3P3_OV_SEL_PROXY — POK_VDDSHV_MAIN_3P3 mode (undervoltage/ping-pong or over-voltage)Field values (others are reserved):1'b0 - UV_OR_PINGPONG1'b1 - OV Reset Source: mod_por_rst_n
  [12] PRG_PP_1_CTRL_POK_VDDSHV_MAIN_1P8_OV_SEL_PROXY — POK_VDDSHV_MAIN_1P8 mode (undervoltage/ping-pong or over-voltage)Field values (others are reserved):1'b0 - UV_OR_PINGPONG1'b1 - OV Reset Source: mod_por_rst_n
  [11] PRG_PP_1_CTRL_POK_VMON_CAP_MCU_GENERAL_OV_SEL_PROXY — POK_VMON_CAP_MCU_GENERAL mode (undervoltage/ping-pong or over-voltage)Field values (others are reserved):1'b0 - UV_OR_PINGPONG1'b1 - OV Reset Source: mod_por_rst_n
  [8] PRG_PP_1_CTRL_POK_VDDR_CORE_OV_SEL_PROXY — POK_VDDR_CORE mode (undervoltage/ping-pong or over-voltage)Field values (others are reserved):1'b0 - UV_OR_PINGPONG1'b1 - OV Reset Source: mod_por_rst_n
  [6] PRG_PP_1_CTRL_POK_VDDS_DDRIO_EN_PROXY — Enable POK_VDDS_DDRIO (if pok_en_sel = 1):Field values (others are reserved):1'b0 - Disabled1'b1 - Enabled Reset Source: mod_por_rst_n
  [5] PRG_PP_1_CTRL_POK_VDDSHV_MAIN_3P3_EN_PROXY — Enable POK_VDDSHV_MAIN_3P3 (if pok_en_sel = 1):Field values (others are reserved):1'b0 - Disabled1'b1 - Enabled Reset Source: mod_por_rst_n
  [4] PRG_PP_1_CTRL_POK_VDDSHV_MAIN_1P8_EN_PROXY — Enable POK_VDDSHV_MAIN_1P8 (if pok_en_sel = 1):Field values (others are reserved):1'b0 - Disabled1'b1 - Enabled Reset Source: mod_por_rst_n
  [3] PRG_PP_1_CTRL_POK_VMON_CAP_MCU_GENERAL_EN_PROXY — Enable POK_VMON_CAP_MCU_GENERAL (if pok_en_sel = 1):Field values (others are reserved):1'b0 - Disabled1'b1 - Enabled Reset Source: mod_por_rst_n
  [0] PRG_PP_1_CTRL_POK_VDDR_CORE_EN_PROXY — Enable POK_VDDR_CORE (if pok_en_sel = 1):Field values (others are reserved):1'b0 - Disabled1'b1 - Enabled Reset Source: mod_por_rst_n
0x1A280 MCU_CTRL_MMRCFG0_CLKGATE_CTRL_PROXY — Controls the power clock gating feature of MCU domain modules and busses
  [0] CLKGATE_CTRL_WKUP_SAFE_CBA_NOGATE_PROXY — WKUP domain CBASS auto clock gate on idle disable. Field values (others are reserved):1'b0 - Auto clock gating enabled1'b1 - Auto clock gating disabled Reset Source: mod_por_rst_n
0x1B008 MCU_CTRL_MMRCFG0_LOCK6_KICK0_PROXY
  [31:0] LOCK6_KICK0_PROXY — - KICK0 component Reset Source: mod_g_rst_n
0x1B00C MCU_CTRL_MMRCFG0_LOCK6_KICK1_PROXY
  [31:0] LOCK6_KICK1_PROXY — - KICK1 component Reset Source: mod_g_rst_n
{0x1B100+4i} MCU_CTRL_MMRCFG0_CLAIMREG_P6_R{i} (i=0..5)
  [31:0] CLAIMREG_P6_R{i} — Claim bits for Partition 6 Reset Source: mod_g_rst_n
